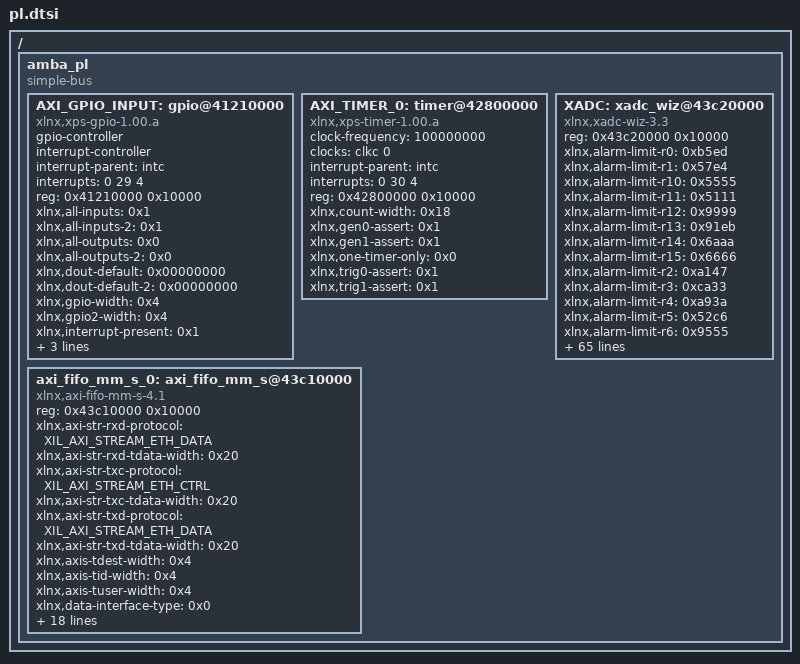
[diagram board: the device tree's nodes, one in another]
/*
 * CAUTION: This file is automatically generated by Xilinx.
 * Version:  
 * Today is: Fri Jun 17 22:00:31 2016
*/


/ {
	amba_pl: amba_pl {
		#address-cells = <1>;
		#size-cells = <1>;
		compatible = "simple-bus";
		ranges ;
		AXI_GPIO_INPUT: gpio@41210000 {
			#gpio-cells = <2>;
			#interrupt-cells = <2>;
			compatible = "xlnx,xps-gpio-1.00.a";
			gpio-controller ;
			interrupt-controller ;
			interrupt-parent = <&intc>;
			interrupts = <0 29 4>;
			reg = <0x41210000 0x10000>;
			xlnx,all-inputs = <0x1>;
			xlnx,all-inputs-2 = <0x1>;
			xlnx,all-outputs = <0x0>;
			xlnx,all-outputs-2 = <0x0>;
			xlnx,dout-default = <0x00000000>;
			xlnx,dout-default-2 = <0x00000000>;
			xlnx,gpio-width = <0x4>;
			xlnx,gpio2-width = <0x4>;
			xlnx,interrupt-present = <0x1>;
			xlnx,is-dual = <0x1>;
			xlnx,tri-default = <0xFFFFFFFF>;
			xlnx,tri-default-2 = <0xFFFFFFFF>;
		};
		AXI_TIMER_0: timer@42800000 {
			clock-frequency = <100000000>;
			clock-names = "ref_clk";
			clocks = "clkc 0";
			compatible = "xlnx,xps-timer-1.00.a";
			interrupt-parent = <&intc>;
			interrupts = <0 30 4>;
			reg = <0x42800000 0x10000>;
			xlnx,count-width = <0x18>;
			xlnx,gen0-assert = <0x1>;
			xlnx,gen1-assert = <0x1>;
			xlnx,one-timer-only = <0x0>;
			xlnx,trig0-assert = <0x1>;
			xlnx,trig1-assert = <0x1>;
		};
		XADC: xadc_wiz@43c20000 {
			compatible = "xlnx,xadc-wiz-3.3";
			reg = <0x43c20000 0x10000>;
			xlnx,alarm-limit-r0 = <0xb5ed>;
			xlnx,alarm-limit-r1 = <0x57e4>;
			xlnx,alarm-limit-r10 = <0x5555>;
			xlnx,alarm-limit-r11 = <0x5111>;
			xlnx,alarm-limit-r12 = <0x9999>;
			xlnx,alarm-limit-r13 = <0x91eb>;
			xlnx,alarm-limit-r14 = <0x6aaa>;
			xlnx,alarm-limit-r15 = <0x6666>;
			xlnx,alarm-limit-r2 = <0xa147>;
			xlnx,alarm-limit-r3 = <0xca33>;
			xlnx,alarm-limit-r4 = <0xa93a>;
			xlnx,alarm-limit-r5 = <0x52c6>;
			xlnx,alarm-limit-r6 = <0x9555>;
			xlnx,alarm-limit-r7 = <0xae4e>;
			xlnx,alarm-limit-r8 = <0x5999>;
			xlnx,alarm-limit-r9 = <0x5111>;
			xlnx,configuration-r0 = <0x0>;
			xlnx,configuration-r1 = <0x21a0>;
			xlnx,configuration-r2 = <0x400>;
			xlnx,dclk-frequency = <0x64>;
			xlnx,external-mux-channel = "VP_VN";
			xlnx,external-muxaddr-enable = <0x0>;
			xlnx,fifo-depth = <0x7>;
			xlnx,has-axi = <0x1>;
			xlnx,has-axi4stream = <0x0>;
			xlnx,has-busy = <0x1>;
			xlnx,has-channel = <0x1>;
			xlnx,has-convst = <0x0>;
			xlnx,has-convstclk = <0x0>;
			xlnx,has-dclk = <0x1>;
			xlnx,has-drp = <0x0>;
			xlnx,has-eoc = <0x1>;
			xlnx,has-eos = <0x1>;
			xlnx,has-external-mux = <0x0>;
			xlnx,has-jtagbusy = <0x0>;
			xlnx,has-jtaglocked = <0x0>;
			xlnx,has-jtagmodified = <0x0>;
			xlnx,has-ot-alarm = <0x1>;
			xlnx,has-reset = <0x0>;
			xlnx,has-temp-bus = <0x0>;
			xlnx,has-user-temp-alarm = <0x1>;
			xlnx,has-vbram-alarm = <0x0>;
			xlnx,has-vccaux-alarm = <0x1>;
			xlnx,has-vccddro-alarm = <0x1>;
			xlnx,has-vccint-alarm = <0x1>;
			xlnx,has-vccpaux-alarm = <0x1>;
			xlnx,has-vccpint-alarm = <0x1>;
			xlnx,has-vn = <0x1>;
			xlnx,has-vp = <0x1>;
			xlnx,include-intr = <0x1>;
			xlnx,sampling-rate = "961538.4615384615";
			xlnx,sequence-r0 = <0x900>;
			xlnx,sequence-r1 = <0xc0c0>;
			xlnx,sequence-r2 = <0x100>;
			xlnx,sequence-r3 = <0xc0c0>;
			xlnx,sequence-r4 = <0x0>;
			xlnx,sequence-r5 = <0xc0c0>;
			xlnx,sequence-r6 = <0x0>;
			xlnx,sequence-r7 = <0xc0c0>;
			xlnx,sim-file-name = "design";
			xlnx,sim-file-rel-path = "./";
			xlnx,sim-file-sel = "Default";
			xlnx,vaux0 = <0x0>;
			xlnx,vaux1 = <0x0>;
			xlnx,vaux10 = <0x0>;
			xlnx,vaux11 = <0x0>;
			xlnx,vaux12 = <0x0>;
			xlnx,vaux13 = <0x0>;
			xlnx,vaux14 = <0x1>;
			xlnx,vaux15 = <0x1>;
			xlnx,vaux2 = <0x0>;
			xlnx,vaux3 = <0x0>;
			xlnx,vaux4 = <0x0>;
			xlnx,vaux5 = <0x0>;
			xlnx,vaux6 = <0x1>;
			xlnx,vaux7 = <0x1>;
			xlnx,vaux8 = <0x0>;
			xlnx,vaux9 = <0x0>;
		};
		axi_fifo_mm_s_0: axi_fifo_mm_s@43c10000 {
			compatible = "xlnx,axi-fifo-mm-s-4.1";
			reg = <0x43c10000 0x10000>;
			xlnx,axi-str-rxd-protocol = "XIL_AXI_STREAM_ETH_DATA";
			xlnx,axi-str-rxd-tdata-width = <0x20>;
			xlnx,axi-str-txc-protocol = "XIL_AXI_STREAM_ETH_CTRL";
			xlnx,axi-str-txc-tdata-width = <0x20>;
			xlnx,axi-str-txd-protocol = "XIL_AXI_STREAM_ETH_DATA";
			xlnx,axi-str-txd-tdata-width = <0x20>;
			xlnx,axis-tdest-width = <0x4>;
			xlnx,axis-tid-width = <0x4>;
			xlnx,axis-tuser-width = <0x4>;
			xlnx,data-interface-type = <0x0>;
			xlnx,has-axis-tdest = <0x0>;
			xlnx,has-axis-tid = <0x0>;
			xlnx,has-axis-tkeep = <0x0>;
			xlnx,has-axis-tstrb = <0x0>;
			xlnx,has-axis-tuser = <0x0>;
			xlnx,rx-fifo-depth = <0x200>;
			xlnx,rx-fifo-pe-threshold = <0x2>;
			xlnx,rx-fifo-pf-threshold = <0x1fb>;
			xlnx,s-axi-id-width = <0x4>;
			xlnx,s-axi4-data-width = <0x20>;
			xlnx,tx-fifo-depth = <0x200>;
			xlnx,tx-fifo-pe-threshold = <0x2>;
			xlnx,tx-fifo-pf-threshold = <0x1fb>;
			xlnx,use-rx-cut-through = <0x0>;
			xlnx,use-rx-data = <0x1>;
			xlnx,use-tx-ctrl = <0x1>;
			xlnx,use-tx-cut-through = <0x0>;
			xlnx,use-tx-data = <0x1>;
		};
	};
};

